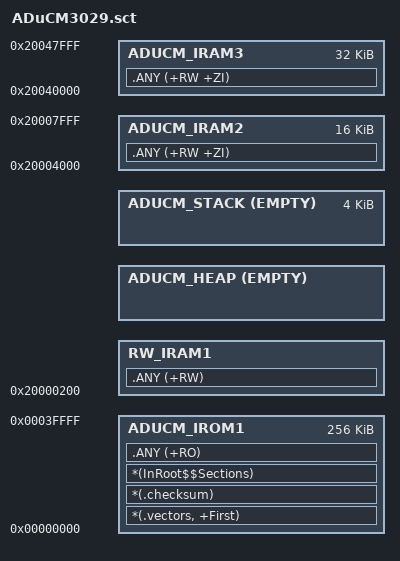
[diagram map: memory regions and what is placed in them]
;******************************************************************************
;  File: ADuCM3029.sct
;  Scatter loading file for Analog Devices ADuCM3029 processor
;
;  Copyright (c) 2011 - 2014 ARM LIMITED
;  Copyright (c) 2016 - 2017 Analog Devices, Inc.
;
;  All rights reserved.
;  Redistribution and use in source and binary forms, with or without
;  modification, are permitted provided that the following conditions are met:
;  - Redistributions of source code must retain the above copyright
;    notice, this list of conditions and the following disclaimer.
;  - Redistributions in binary form must reproduce the above copyright
;    notice, this list of conditions and the following disclaimer in the
;    documentation and/or other materials provided with the distribution.
;  - Neither the name of ARM nor the names of its contributors may be used
;    to endorse or promote products derived from this software without
;    specific prior written permission.
;
;  THIS SOFTWARE IS PROVIDED BY THE COPYRIGHT HOLDERS AND CONTRIBUTORS "AS IS"
;  AND ANY EXPRESS OR IMPLIED WARRANTIES, INCLUDING, BUT NOT LIMITED TO, THE
;  IMPLIED WARRANTIES OF MERCHANTABILITY AND FITNESS FOR A PARTICULAR PURPOSE
;  ARE DISCLAIMED. IN NO EVENT SHALL COPYRIGHT HOLDERS AND CONTRIBUTORS BE
;  LIABLE FOR ANY DIRECT, INDIRECT, INCIDENTAL, SPECIAL, EXEMPLARY, OR
;  CONSEQUENTIAL DAMAGES (INCLUDING, BUT NOT LIMITED TO, PROCUREMENT OF
;  SUBSTITUTE GOODS OR SERVICES; LOSS OF USE, DATA, OR PROFITS; OR BUSINESS
;  INTERRUPTION) HOWEVER CAUSED AND ON ANY THEORY OF LIABILITY, WHETHER IN
;  CONTRACT, STRICT LIABILITY, OR TORT (INCLUDING NEGLIGENCE OR OTHERWISE)
;  ARISING IN ANY WAY OUT OF THE USE OF THIS SOFTWARE, EVEN IF ADVISED OF THE
;  POSSIBILITY OF SUCH DAMAGE.
;
;  Portions Copyright (c) 2017 Analog Devices, Inc.
;
;******************************************************************************

LR_IROM1 0x00000000 0x00040000 {
    ADUCM_IROM1 0x00000000 0x00040000 {  ; romflash start address
        *(.vectors, +First)
        *(.checksum)
        *(InRoot$$Sections)
        .ANY (+RO)
    }

    RW_IRAM1 0x20000200 { ; data section
        .ANY (+RW)
    }

    ADUCM_HEAP AlignExpr(+0, 16) EMPTY
        (0x20003000 - AlignExpr(ImageLimit(RW_IRAM1), 16)) { ; heap
    }

    ADUCM_STACK AlignExpr(+0, 16) EMPTY 0x1000 { ; stack
    }

    ADUCM_IRAM2 0x20004000 0x4000 { ; bss section
        .ANY (+RW +ZI)
    }

    ADUCM_IRAM3 0x20040000 0x8000 { ; non-retainable memory region
         .ANY (+RW +ZI)
    }
}

ScatterAssert(ImageLimit(RW_IRAM1)    <= 0x20002000)

